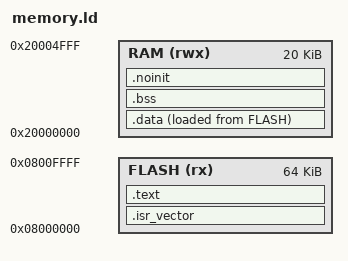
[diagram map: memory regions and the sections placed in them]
ENTRY(Reset_Handler)

MEMORY
{
    FLASH (rx)  : ORIGIN = 0x08000000, LENGTH = 64K
    RAM   (rwx) : ORIGIN = 0x20000000, LENGTH = 20K
}

_estack = ORIGIN(RAM) + LENGTH(RAM);

SECTIONS
{
    .isr_vector :
    {
        . = ALIGN(256);
        KEEP(*(.isr_vector))
        . = ALIGN(4);
    } > FLASH

    .text :
    {
        . = ALIGN(4);
        _stext = .;
        *(.text)
        *(.text*)
        *(.rodata)
        *(.rodata*)
        . = ALIGN(4);
        _etext = .;
    } > FLASH

    _sidata = LOADADDR(.data);

    .data :
    {
        . = ALIGN(4);
        _sdata = .;
        *(.data)
        *(.data*)
        . = ALIGN(4);
        _edata = .;
    } > RAM AT > FLASH

    .bss (NOLOAD) :
    {
        . = ALIGN(4);
        _sbss = .;
        *(.bss)
        *(.bss*)
        *(COMMON)
        . = ALIGN(4);
        _ebss = .;
    } > RAM

    .noinit (NOLOAD) :
    {
        . = ALIGN(4);
        _snoinit = .;
        *(.noinit)
        *(.noinit*)
        . = ALIGN(4);
        _enoinit = .;
    } > RAM

    _flash_start = ORIGIN(FLASH);
    _flash_end   = ORIGIN(FLASH) + LENGTH(FLASH);
    _ram_start   = ORIGIN(RAM);
    _ram_end     = ORIGIN(RAM) + LENGTH(RAM);

    /DISCARD/ :
    {
        *(.comment)
        *(.note*)
    }
}
